# VPAC0_VPAC_REGS_VPAC_REGS_CFG_IP_MMRS register map
Vendor: Texas Instruments
Peripheral module from a debugger description file (folder J7ES).
Registers are 32-bit, read-only, reset 0x64C01100 unless marked. A register's access mark holds for its fields unless they carry their own. Offsets are as the file gives them; lines under a group give offsets from that group; [hi:lo] are bit positions; {n}, {i} and the like mark numbered series; 'fields as' and 'values as' point back to an identical list; <NAME> marks a mode.

## VPAC0_VPAC_REGS_VPAC_REGS_CFG_IP_MMRS
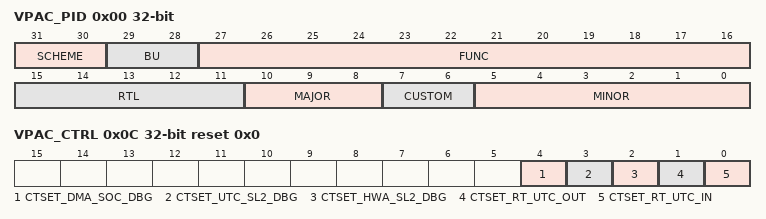
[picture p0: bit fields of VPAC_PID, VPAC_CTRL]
0x00 VPAC_PID
  [31:30] SCHEME — Used to distinguish between old scheme and new scheme.
  [29:28] BU — BU indicator
  [27:16] FUNC — Function indicates a software compatible module family.
  [15:11] RTL — RTL Version.
  [10:8] MAJOR — Major Revision.
  [7:6] CUSTOM — Indicates a special version for a particular device.
  [5:0] MINOR — Minor Revision.
0x0C VPAC_CTRL rw reset 0x0 — Register to control and do event selection for VPAC module
  [4] CTSET_DMA_SOC_DBG — select config for CTSET
  [3] CTSET_UTC_SL2_DBG — select config for CTSET
  [2] CTSET_HWA_SL2_DBG — select config for CTSET
  [1] CTSET_RT_UTC_OUT — select config for CTSET
  [0] CTSET_RT_UTC_IN — select config for CTSET
